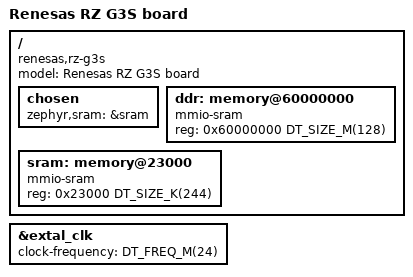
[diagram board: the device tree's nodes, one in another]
/*
 * Copyright (c) 2024 EPAM Systems
 *
 * SPDX-License-Identifier: Apache-2.0
 */

/dts-v1/;
#include <arm/renesas/rz/r9a08g045.dtsi>
#include <freq.h>
#include <mem.h>

/ {
	model = "Renesas RZ G3S board";
	compatible = "renesas,rz-g3s";

	chosen {
		zephyr,sram = &sram;
	};

	ddr: memory@60000000 {
		compatible = "mmio-sram";
		reg = <0x60000000 DT_SIZE_M(128)>;
	};

	sram: memory@23000 {
		compatible = "mmio-sram";
		reg = <0x23000 DT_SIZE_K(244)>;
	};
};

&extal_clk {
	clock-frequency = <DT_FREQ_M(24)>;
};
